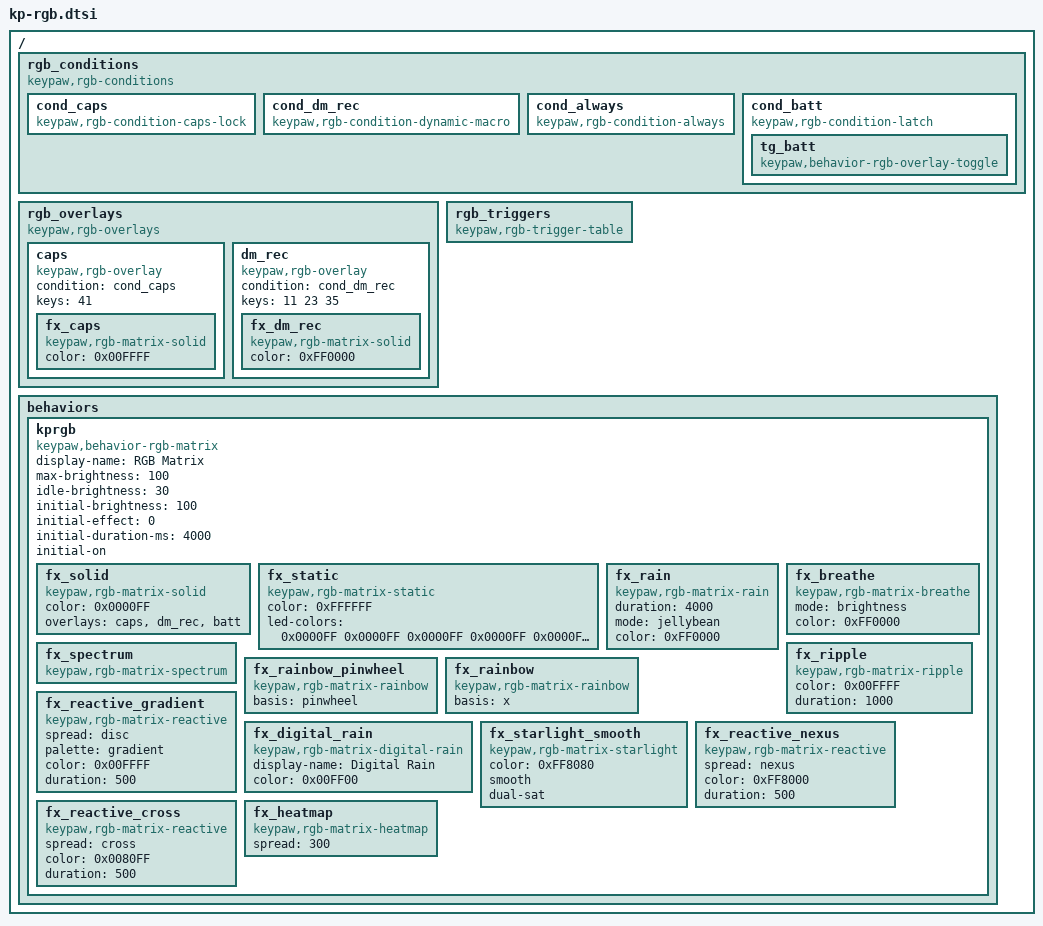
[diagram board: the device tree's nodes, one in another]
/*
 * Copyright (c) 2026 The ZMK Contributors
 *
 * SPDX-License-Identifier: MIT
 */

#include <dt-bindings/zmk/rgb.h>

/ {
    // Conditions are reusable predicates for overlays and triggers
    rgb_conditions: rgb_conditions {
        compatible = "keypaw,rgb-conditions";

        // On when the host reports CapsLock on
        cond_caps: cond_caps {
            compatible = "keypaw,rgb-condition-caps-lock";
        };

        // On when our dynamic macro module is recording
        cond_dm_rec: cond_dm_rec {
            compatible = "keypaw,rgb-condition-dynamic-macro";
        };

        // A always-true condition
        cond_always: cond_always {
            compatible = "keypaw,rgb-condition-always";
        };

        // A manually toggled condition, toggled by the nested `&tg_batt` behavior
        cond_batt: cond_batt {
            compatible = "keypaw,rgb-condition-latch";

            tg_batt: tg_batt {
                compatible = "keypaw,behavior-rgb-overlay-toggle";
                #binding-cells = <0>;
            };
        };
    };

    // The `rgb_overlays` container is the overlay registry.
    // The indices of overlays in it is used as IDs to sync between split halves.
    rgb_overlays: rgb_overlays {
        compatible = "keypaw,rgb-overlays";

        caps: caps {
            compatible = "keypaw,rgb-overlay";
            condition = <&cond_caps>;
            keys = <41>;
            fx_caps {
                compatible = "keypaw,rgb-matrix-solid";
                #binding-cells = <0>;
                color = <0x00FFFF>;
            };
        };

        dm_rec: dm_rec {
            compatible = "keypaw,rgb-overlay";
            condition = <&cond_dm_rec>;
            keys = <11 23 35>;
            fx_dm_rec {
                compatible = "keypaw,rgb-matrix-solid";
                #binding-cells = <0>;
                color = <0xFF0000>;
            };
        };

        // Layer and battery overlays are defined in keypaw48.keymap, which is
        // what fixes the paint order: it is the declaration order here.
    };

    // Condition -> command rules, evaluated on the central and pushed to both
    // halves. The table's children are the triggers, and their DECLARATION
    // ORDER is the precedence order: the first one whose condition is active
    // wins.
    //
    // There is deliberately no `triggers = <...>;` list here: every devicetree
    // node depends on its parent, so a parent pointing at its own child is a
    // phandle cycle. And these nodes are NOT children of &kprgb, whose children
    // are the effect registry (an effect is identified by its position there)
    // -- besides which the bindings below reference &kprgb back.
    rgb_triggers: rgb_triggers {
        compatible = "keypaw,rgb-trigger-table";
        // The actual triggers are defined in keypaw48.keymap.
    };

    // A multi-zone setup can declare another sibling behavior with its own
    // effect registry. Keep each behavior name <= 8 characters for split:
    //
    // rgb_main: rgb_main {
    //     compatible = "keypaw,behavior-rgb-matrix";
    //     #binding-cells = <2>;
    //     leds = <0 1 2 3 4 5 6 7>;
    //     fx_main: fx_main {
    //         compatible = "keypaw,rgb-matrix-solid";
    //         #binding-cells = <0>;
    //     };
    // };
    // rgb_num: rgb_num {
    //     compatible = "keypaw,behavior-rgb-matrix";
    //     #binding-cells = <2>;
    //     leds = <8 9 10 11 12 13 14 15>;
    //     fx_num: fx_num {
    //         compatible = "keypaw,rgb-matrix-solid";
    //         #binding-cells = <0>;
    //     };
    // };

    behaviors {
        // Behavior can be invoked on peripherals, so name must be <= 8 characters.
        kprgb: kprgb {
            compatible = "keypaw,behavior-rgb-matrix";
            #binding-cells = <2>;
            display-name = "RGB Matrix";

            max-brightness = <100>;
            idle-brightness = <30>;
            initial-brightness = <100>;
            initial-effect = <0>;
            initial-duration-ms = <4000>;
            initial-on;

            // Declaration order is the identity: an effect's position among
            // these children is the slot that travels the split link as a
            // single byte.
            fx_solid: fx_solid {
                compatible = "keypaw,rgb-matrix-solid";
                #binding-cells = <0>;
                color = <0x0000FF>;
                // Per-effect override: only the Caps LED, the dynamic-macro
                // recording LED and the battery gauge are composited here.
                // fx_solid is initial-effect, so dm_rec must be listed or
                // recording feedback would be dark at boot, and batt must be
                // listed or the gauge would be invisible while solid is active.
                overlays = <&caps &dm_rec &batt>;
            };
            fx_static: fx_static {
                compatible = "keypaw,rgb-matrix-static";
                #binding-cells = <0>;
                color = <0xFFFFFF>;
                /* Per-LED colours indexed by strip chain position (left half has
                 * 30 LEDs). A stand-in for QMK ALPHAS_MODS: alternate hues to
                 * show per-key control. Edit to taste. */
                led-colors = <
                    0x0000FF 0x0000FF 0x0000FF 0x0000FF 0x0000FF 0x0000FF
                    0xFF0000 0xFF0000 0xFF0000 0xFF0000 0xFF0000 0xFF0000
                    0x0000FF 0x0000FF 0x0000FF 0x0000FF 0x0000FF 0x0000FF
                    0xFF0000 0xFF0000 0xFF0000 0xFF0000 0xFF0000 0xFF0000
                    0x00FF00 0x00FF00 0x00FF00 0x00FF00 0x00FF00 0x00FF00
                >;
            };
            /* Stochastic fields share compatible families; attributes pick the
             * sub-effect. Instantiate more nodes for extra cycle entries. */
            fx_rain: fx_rain {
                compatible = "keypaw,rgb-matrix-rain";
                #binding-cells = <0>;
                duration = <4000>;
                mode = "jellybean";
                color = <0xFF0000>;
            };
            fx_breathe: fx_breathe {
                compatible = "keypaw,rgb-matrix-breathe";
                #binding-cells = <0>;
                mode = "brightness";
                color = <0xFF0000>;
            };
            fx_spectrum: fx_spectrum {
                compatible = "keypaw,rgb-matrix-spectrum";
                #binding-cells = <0>;
            };
            fx_ripple: fx_ripple {
                compatible = "keypaw,rgb-matrix-ripple";
                #binding-cells = <0>;
                color = <0x00FFFF>;
                duration = <1000>;
            };
            fx_rainbow_pinwheel: fx_rainbow_pinwheel {
                compatible = "keypaw,rgb-matrix-rainbow";
                #binding-cells = <0>;
                basis = "pinwheel";
            };
            fx_rainbow: fx_rainbow {
                compatible = "keypaw,rgb-matrix-rainbow";
                #binding-cells = <0>;
                basis = "x";
            };
            fx_reactive_gradient: fx_reactive_gradient {
                compatible = "keypaw,rgb-matrix-reactive";
                #binding-cells = <0>;
                spread = "disc";
                palette = "gradient";
                color = <0x00FFFF>;
                duration = <500>;
            };
            fx_digital_rain: fx_digital_rain {
                compatible = "keypaw,rgb-matrix-digital-rain";
                #binding-cells = <0>;
                display-name = "Digital Rain";
                color = <0x00FF00>;
            };
            fx_starlight_smooth: fx_starlight_smooth {
                compatible = "keypaw,rgb-matrix-starlight";
                #binding-cells = <0>;
                color = <0xFF8080>;
                smooth;
                dual-sat;
            };
            fx_reactive_nexus: fx_reactive_nexus {
                compatible = "keypaw,rgb-matrix-reactive";
                #binding-cells = <0>;
                spread = "nexus";
                color = <0xFF8000>;
                duration = <500>;
            };
            fx_reactive_cross: fx_reactive_cross {
                compatible = "keypaw,rgb-matrix-reactive";
                #binding-cells = <0>;
                spread = "cross";
                color = <0x0080FF>;
                duration = <500>;
            };
            fx_heatmap: fx_heatmap {
                compatible = "keypaw,rgb-matrix-heatmap";
                #binding-cells = <0>;
                spread = <300>;
            };
        };
    };
};
